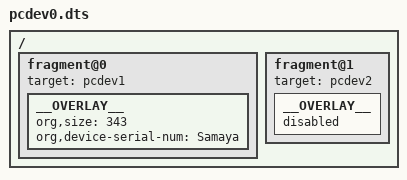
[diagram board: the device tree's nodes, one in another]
/dts-v1/;
/plugin/;

/{

  fragment@0 {
   target = <&pcdev1>;
   __OVERLAY__ {
    org,size = <343>;
    org,device-serial-num = "Samaya";
    };
  };

  fragment@1 {
   target = <&pcdev2>;
   __OVERLAY__ {
   status = "disabled";
   };
  };

};
